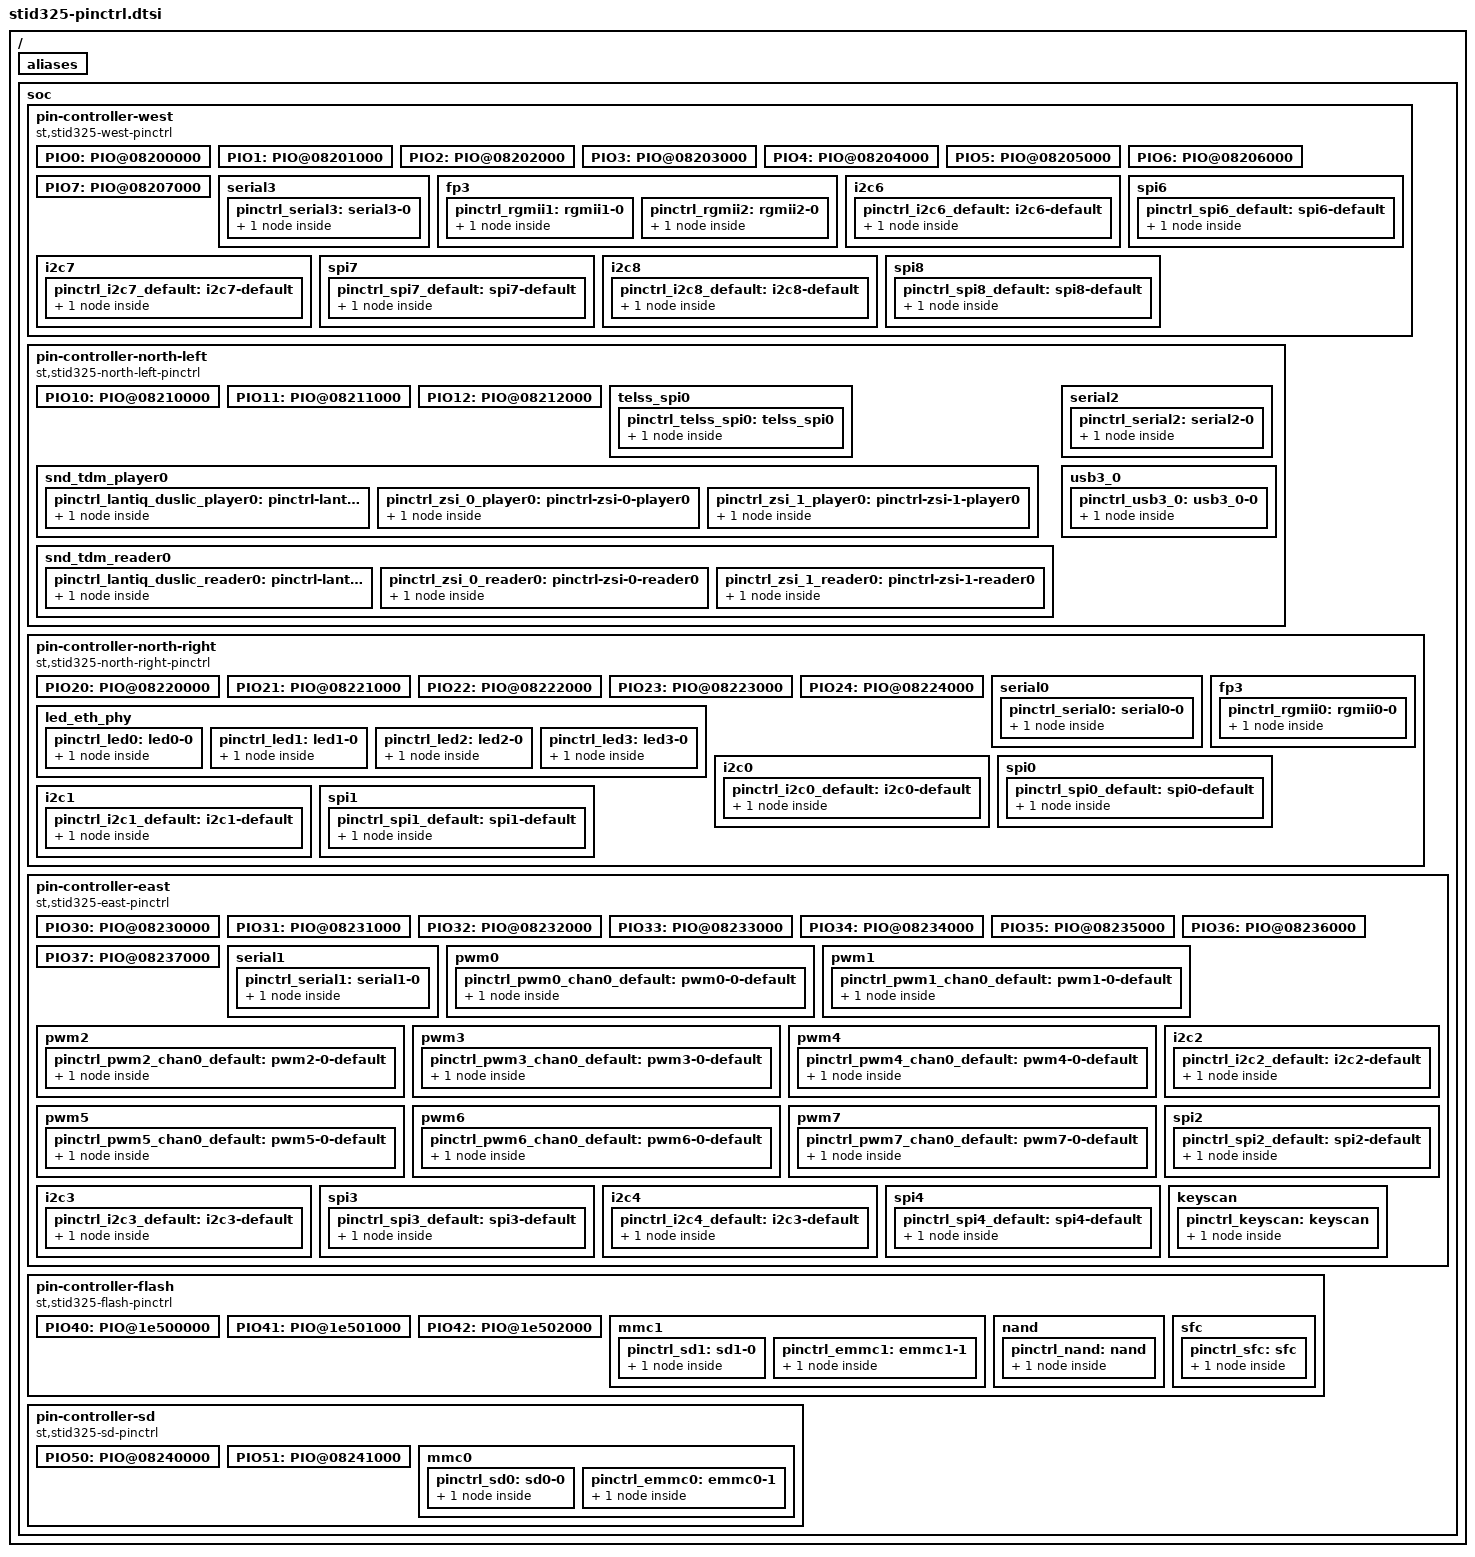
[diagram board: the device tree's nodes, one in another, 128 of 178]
/*
 * Copyright (C) 2015 STMicroelectronics Limited.
 * Author: Carmelo Amoroso <carmelo.amoroso@st.com>
 * Author: Giuseppe Cavallaro <peppe.cavallaro@st.com>
 *
 * This program is free software; you can redistribute it and/or modify
 * it under the terms of the GNU General Public License version 2 as
 * publishhed by the Free Software Foundation.
 */

#include <dt-bindings/pinctrl/st-pincfg.h>
#include <dt-bindings/interrupt-controller/arm-gic.h>

/ {
	aliases {
		/* PIOs for FC_BACKBONE */

		/* PIOs WEST Partition: 0-7 */
		gpio0 = &PIO0;
		gpio1 = &PIO1;
		gpio2 = &PIO2;
		gpio3 = &PIO3;
		gpio4 = &PIO4;
		gpio5 = &PIO5;
		gpio6 = &PIO6;
		gpio7 = &PIO7;

		/* PIOs NORTH_LEFT Partition: 10-12 */
		gpio8 = &PIO10;
		gpio9 = &PIO11;
		gpio10 = &PIO12;

		/* PIOs NORTH_RIGHT Partition: 20-24 */
		gpio11 = &PIO20;
		gpio12 = &PIO21;
		gpio13 = &PIO22;
		gpio14 = &PIO23;
		gpio15 = &PIO24;

		/* PIOs EAST Partition: 30-37 */
		gpio16 = &PIO30;
		gpio17 = &PIO31;
		gpio18 = &PIO32;
		gpio19 = &PIO33;
		gpio20 = &PIO34;
		gpio21 = &PIO35;
		gpio22 = &PIO36;
		gpio23 = &PIO37;

		/* PIOs SOUTH FLASH: 40-42 */
		gpio24 = &PIO40;
		gpio25 = &PIO41;
		gpio26 = &PIO42;

		/* PIOs SD Partition: 50-51 */
		gpio27 = &PIO50;
		gpio28 = &PIO51;
	};

	soc {
		/* FC_BACKBONE PIO_WEST */
		pin-controller-west {
			#address-cells = <1>;
			#size-cells = <1>;
			compatible = "st,stid325-west-pinctrl";
			st,syscfg = <&syscfg_pio_west>;
			ranges = <0 0x08200000 0x8000>;
			reg = <0x0820f080 0x4>;
			reg-names = "irqmux";
			interrupts = <GIC_SPI 185 IRQ_TYPE_NONE>;
			interrupts-names = "irqmux";

			PIO0: PIO@08200000 {
				gpio-controller;
				#gpio-cells = <2>;
				reg = <0x0 0x100>;
				st,bank-name = "PIO0";
				interrupt-controller;
				#interrupt-cells = <2>;
			};

			PIO1: PIO@08201000 {
				gpio-controller;
				#gpio-cells = <2>;
				reg = <0x1000 0x100>;
				st,bank-name = "PIO1";
				interrupt-controller;
				#interrupt-cells = <2>;
			};

			PIO2: PIO@08202000 {
				gpio-controller;
				#gpio-cells = <2>;
				reg = <0x2000 0x100>;
				st,bank-name = "PIO2";
				interrupt-controller;
				#interrupt-cells = <2>;
			};

			PIO3: PIO@08203000 {
				gpio-controller;
				#gpio-cells = <2>;
				reg = <0x3000 0x100>;
				st,bank-name = "PIO3";
				interrupt-controller;
				#interrupt-cells = <2>;
			};

			PIO4: PIO@08204000 {
				gpio-controller;
				#gpio-cells = <2>;
				reg = <0x4000 0x100>;
				st,bank-name = "PIO4";
				interrupt-controller;
				#interrupt-cells = <2>;
			};

			PIO5: PIO@08205000 {
				gpio-controller;
				#gpio-cells = <2>;
				reg = <0x5000 0x100>;
				st,bank-name = "PIO5";
				interrupt-controller;
				#interrupt-cells = <2>;
			};

			PIO6: PIO@08206000 {
				gpio-controller;
				#gpio-cells = <2>;
				reg = <0x6000 0x100>;
				st,bank-name = "PIO6";
				interrupt-controller;
				#interrupt-cells = <2>;
			};

			PIO7: PIO@08207000 {
				gpio-controller;
				#gpio-cells = <2>;
				reg = <0x7000 0x100>;
				st,bank-name = "PIO7";
				interrupt-controller;
				#interrupt-cells = <2>;
			};

			serial3 {
				pinctrl_serial3: serial3-0 {
					st,pins {
						tx = <&PIO7 0 ALT1 OUT>;
						rx = <&PIO7 1 ALT1 IN>;
					};
				};
			};

			/* RGMII 1,2*/
			fp3 {
				pinctrl_rgmii1: rgmii1-0 {
					st,pins {
						txd0 = <&PIO0 0 ALT1 OUT DE_IO 0 CLK_A>;
						txd1 = <&PIO0 1 ALT1 OUT DE_IO 0 CLK_A>;
						txd2 = <&PIO0 2 ALT1 OUT DE_IO 0 CLK_A>;
						txd3 = <&PIO0 3 ALT1 OUT DE_IO 0 CLK_A>;
						txctl = <&PIO0 4 ALT1 OUT NICLK 0 CLK_A>;
						txclk = <&PIO0 5 ALT1 OUT NICLK 0 CLK_A>;
						rxd0 = <&PIO0 6 ALT1 IN DE_IO 0 CLK_A>;
						rxd1 = <&PIO0 7 ALT1 IN DE_IO 0 CLK_A>;
						rxd2 = <&PIO1 0 ALT1 IN DE_IO 0 CLK_A>;
						rxd3 = <&PIO1 1 ALT1 IN DE_IO 0 CLK_A>;
						rxctl = <&PIO1 2 ALT1 IN DE_IO 0 CLK_A>;
						rxclk = <&PIO1 3 ALT1 IN NICLK 0 CLK_A>;
						phyclk = <&PIO1 4 ALT1 OUT NICLK 0 CLK_B>;
					};
				};
				pinctrl_rgmii2: rgmii2-0 {
					st,pins {
						mdio = <&PIO1 5 ALT1 BIDIR BYPASS 0>;
						mdc = <&PIO1 6 ALT1 OUT NICLK 0 CLK_A>;
						mdint = <&PIO1 7 ALT1 IN DE_IO 0 CLK_A>;
						txd0 = <&PIO2 0 ALT1 OUT DE_IO 0 CLK_A>;
						txd1 = <&PIO2 1 ALT1 OUT DE_IO 0 CLK_A>;
						txd2 = <&PIO2 2 ALT1 OUT DE_IO 0 CLK_A>;
						txd3 = <&PIO2 3 ALT1 OUT DE_IO 0 CLK_A>;
						txctl = <&PIO2 4 ALT1 OUT NICLK 0 CLK_A>;
						txclk = <&PIO2 5 ALT1 OUT NICLK 0 CLK_A>;
						rxd0 = <&PIO2 6 ALT1 IN DE_IO 0 CLK_A>;
						rxd1 = <&PIO2 7 ALT1 IN DE_IO 0 CLK_A>;
						rxd2 = <&PIO3 0 ALT1 IN DE_IO 0 CLK_A>;
						rxd3 = <&PIO3 1 ALT1 IN DE_IO 0 CLK_A>;
						rxctl = <&PIO3 2 ALT1 IN DE_IO 0 CLK_A>;
						rxclk = <&PIO3 3 ALT1 IN NICLK 0 CLK_A>;
						phyclk = <&PIO3 4 ALT1 OUT NICLK 0 CLK_B>;
					};
				};
			};

			i2c6 {
				pinctrl_i2c6_default: i2c6-default {
					st,pins {
						sda = <&PIO5 6 ALT1 BIDIR>;
						scl = <&PIO5 5 ALT1 BIDIR>;
					};
				};
			};
			spi6 {
				pinctrl_spi6_default: spi6-default {
					st,pins {
						mtsr = <&PIO5 6 ALT1 BIDIR>;
						mrst = <&PIO5 7 ALT1 BIDIR>;
						scl = <&PIO5 5 ALT1 BIDIR>;
					};
				};
			};
			i2c7 {
				pinctrl_i2c7_default: i2c7-default {
					st,pins {
						sda = <&PIO5 3 ALT1 BIDIR>;
						scl = <&PIO5 2 ALT1 BIDIR>;
					};
				};
			};
			spi7 {
				pinctrl_spi7_default: spi7-default {
					st,pins {
						mtsr = <&PIO6 3 ALT1 BIDIR>;
						mrst = <&PIO6 4 ALT1 BIDIR>;
						scl = <&PIO6 2 ALT1 BIDIR>;
					};
				};
			};
			i2c8 {
				pinctrl_i2c8_default: i2c8-default {
					st,pins {
						sda = <&PIO6 6 ALT1 BIDIR>;
						scl = <&PIO6 5 ALT1 BIDIR>;
					};
				};
			};
			spi8 {
				pinctrl_spi8_default: spi8-default {
					st,pins {
						mtsr = <&PIO6 6 ALT1 BIDIR>;
						mrst = <&PIO6 7 ALT1 BIDIR>;
						scl = <&PIO6 5 ALT1 BIDIR>;
					};
				};
			};
		};

		/* FC_BACKBONE PIO_NORTH_LEFT */
		pin-controller-north-left {
			#address-cells = <1>;
			#size-cells = <1>;
			compatible = "st,stid325-north-left-pinctrl";
			st,syscfg = <&syscfg_pio_north_left>;
			ranges = <0 0x08210000 0x3000>;
			reg = <0x0821f080 0x4>;
			reg-names = "irqmux";
			interrupts = <GIC_SPI 183 IRQ_TYPE_NONE>;
			interrupts-names = "irqmux";

			PIO10: PIO@08210000 {
				gpio-controller;
				#gpio-cells = <2>;
				reg = <0x0 0x100>;
				st,bank-name = "PIO10";
				interrupt-controller;
				#interrupt-cells = <2>;
			};

			PIO11: PIO@08211000 {
				gpio-controller;
				#gpio-cells = <2>;
				reg = <0x1000 0x100>;
				st,bank-name = "PIO11";
				interrupt-controller;
				#interrupt-cells = <2>;
			};

			PIO12: PIO@08212000 {
				gpio-controller;
				#gpio-cells = <2>;
				reg = <0x2000 0x100>;
				st,bank-name = "PIO12";
				interrupt-controller;
				#interrupt-cells = <2>;
			};

			telss_spi0 {
				pinctrl_telss_spi0: telss_spi0 {
					st,pins {
						tel-spi-clk = <&PIO11 1 ALT1 OUT>;
						tel-spi-mosi = <&PIO11 2 ALT1 OUT>;
						tel-spi-miso = <&PIO11 3 ALT1 IN>;
					};
				};
			};

			snd_tdm_player0 {
				pinctrl_lantiq_duslic_player0: pinctrl-lantiq-duslic-player0 {
					st,pins {
						PCLK = <&PIO10 5 ALT1 OUT>;
						DTX = <&PIO10 6 ALT1 OUT>;
						FSYNC = <&PIO12 0 ALT2 OUT>;
					};
				};
				pinctrl_zsi_0_player0: pinctrl-zsi-0-player0 {
					st,pins {
						PCLK = <&PIO11 7 ALT1 OUT>;
						DTX = <&PIO12 1 ALT1 OUT>;
						FSYNC = <&PIO12 0 ALT1 OUT>;
					};
				};
				pinctrl_zsi_1_player0: pinctrl-zsi-1-player0 {
					st,pins {
						PCLK = <&PIO11 0 ALT2 OUT>;
						DTX = <&PIO11 5 ALT2 OUT>;
						FSYNC = <&PIO11 4 ALT2 OUT>;
					};
				};
			};

			snd_tdm_reader0 {
				pinctrl_lantiq_duslic_reader0: pinctrl-lantiq-duslic-reader0 {
					st,pins {
						DRX = <&PIO10 7 ALT1 IN>;
					};
				};
				pinctrl_zsi_0_reader0: pinctrl-zsi-0-reader0 {
					st,pins {
						DRX = <&PIO12 2 ALT1 IN>;
					};
				};
				pinctrl_zsi_1_reader0: pinctrl-zsi-1-reader0 {
					st,pins {
						DRX = <&PIO11 6 ALT2 IN>;
					};
				};
			};

			serial2 {
				pinctrl_serial2: serial2-0 {
					st,pins {
						tx = <&PIO12 3 ALT1 OUT>;
						rx = <&PIO12 4 ALT1 IN>;
					};
				};
			};

			usb3_0 {
				pinctrl_usb3_0: usb3_0-0 {
					st,pins {
						oc-detect = <&PIO12 5 ALT1 IN>;
						pwr-enable = <&PIO12 6 ALT1 OUT>;
					};
				};
			};
		};

		/* FC_BACKBONE PIO_NORTH_RIGHT */
		pin-controller-north-right {
			#address-cells = <1>;
			#size-cells = <1>;
			compatible = "st,stid325-north-right-pinctrl";
			st,syscfg = <&syscfg_pio_north_right>;
			ranges = <0 0x08220000 0x5000>;
			reg = <0x0822f080 0x4>;
			reg-names = "irqmux";
			interrupts = <GIC_SPI 184 IRQ_TYPE_NONE>;
			interrupts-names = "irqmux";

			PIO20: PIO@08220000 {
				gpio-controller;
				#gpio-cells = <2>;
				reg = <0x0 0x100>;
				st,bank-name = "PIO20";
				interrupt-controller;
				#interrupt-cells = <2>;
			};

			PIO21: PIO@08221000 {
				gpio-controller;
				#gpio-cells = <2>;
				reg = <0x1000 0x100>;
				st,bank-name = "PIO21";
				interrupt-controller;
				#interrupt-cells = <2>;
			};

			PIO22: PIO@08222000 {
				gpio-controller;
				#gpio-cells = <2>;
				reg = <0x2000 0x100>;
				st,bank-name = "PIO22";
				interrupt-controller;
				#interrupt-cells = <2>;
			};

			PIO23: PIO@08223000 {
				gpio-controller;
				#gpio-cells = <2>;
				reg = <0x3000 0x100>;
				st,bank-name = "PIO23";
				interrupt-controller;
				#interrupt-cells = <2>;
			};

			PIO24: PIO@08224000 {
				gpio-controller;
				#gpio-cells = <2>;
				reg = <0x4000 0x100>;
				st,bank-name = "PIO24";
				interrupt-controller;
				#interrupt-cells = <2>;
			};

			serial0 {
				pinctrl_serial0: serial0-0 {
					st,pins {
						tx = <&PIO23 0 ALT1 OUT>;
						rx = <&PIO23 1 ALT1 IN>;
					};
				};
			};

			/* RGMII 0 */
			fp3 {
				pinctrl_rgmii0: rgmii0-0 {
					st,pins {
						txd0 = <&PIO21 0 ALT1 OUT DE_IO 0 CLK_A>;
						txd1 = <&PIO21 1 ALT1 OUT DE_IO 0 CLK_A>;
						txd2 = <&PIO21 2 ALT1 OUT DE_IO 0 CLK_A>;
						txd3 = <&PIO21 3 ALT1 OUT DE_IO 0 CLK_A>;
						txctl = <&PIO21 4 ALT1 OUT NICLK 0 CLK_A>;
						txclk = <&PIO21 5 ALT1 OUT NICLK 0 CLK_A>;
						rxd0 = <&PIO21 6 ALT1 IN DE_IO 0 CLK_A>;
						rxd1 = <&PIO21 7 ALT1 IN DE_IO 0 CLK_A>;
						rxd2 = <&PIO22 0 ALT1 IN DE_IO 0 CLK_A>;
						rxd3 = <&PIO22 1 ALT1 IN DE_IO 0 CLK_A>;
						rxctl = <&PIO22 2 ALT1 IN DE_IO 0 CLK_A>;
						rxclk = <&PIO22 3 ALT1 IN NICLK 0 CLK_A>;
						phyclk = <&PIO22 4 ALT1 OUT NICLK 0 CLK_B>;
						mdio = <&PIO22 5 ALT1 BIDIR BYPASS 0>;
						mdc = <&PIO22 6 ALT1 OUT NICLK 0 CLK_A>;
						mdint = <&PIO22 7 ALT1 IN DE_IO 0 CLK_A>;
					};
				};
			};

			/* LED Control for ETH PHY */
			led_eth_phy {
				pinctrl_led0: led0-0 {
					st,pins {
						blinkb = <&PIO20 0 ALT1 OUT>;
						txrxb = <&PIO20 1 ALT1 OUT>;
					};
				};
				pinctrl_led1: led1-0 {
					st,pins {
						blinkb = <&PIO20 2 ALT1 OUT>;
						txrxb = <&PIO20 3 ALT1 OUT>;
					};
				};
				pinctrl_led2: led2-0 {
					st,pins {
						blinkb = <&PIO20 4 ALT1 OUT>;
						txrxb = <&PIO20 5 ALT1 OUT>;
					};
				};
				pinctrl_led3: led3-0 {
					st,pins {
						blinkb = <&PIO20 6 ALT1 OUT>;
						txrxb = <&PIO20 7 ALT1 OUT>;
					};
				};
			};

			i2c0 {
				pinctrl_i2c0_default: i2c0-default {
					st,pins {
						sda = <&PIO23 5 ALT1 BIDIR>;
						scl = <&PIO23 4 ALT1 BIDIR>;
					};
				};
			};
			spi0 {
				pinctrl_spi0_default: spi0-default {
					st,pins {
						mtsr = <&PIO23 5 ALT1 BIDIR>;
						mrst = <&PIO23 6 ALT1 BIDIR>;
						scl = <&PIO23 4 ALT1 BIDIR>;
					};
				};
			};
			i2c1 {
				pinctrl_i2c1_default: i2c1-default {
					st,pins {
						sda = <&PIO24 0 ALT1 BIDIR>;
						scl = <&PIO23 7 ALT1 BIDIR>;
					};
				};
			};
			spi1 {
				pinctrl_spi1_default: spi1-default {
					st,pins {
						mtsr = <&PIO24 0 ALT1 BIDIR>;
						mrst = <&PIO24 1 ALT1 BIDIR>;
						scl = <&PIO23 7 ALT1 BIDIR>;
					};
				};
			};
		};

		/* FC_BACKBONE PIO_EAST */
		pin-controller-east {
			#address-cells = <1>;
			#size-cells = <1>;
			compatible = "st,stid325-east-pinctrl";
			st,syscfg = <&syscfg_pio_east>;
			ranges = <0 0x08230000 0x8000>;
			reg = <0x0823f080 0x4>;
			reg-names = "irqmux";
			interrupts = <GIC_SPI 186 IRQ_TYPE_NONE>;
			interrupts-names = "irqmux";

			PIO30: PIO@08230000 {
				gpio-controller;
				#gpio-cells = <2>;
				reg = <0x0 0x100>;
				st,bank-name = "PIO30";
				interrupt-controller;
				#interrupt-cells = <2>;
			};

			PIO31: PIO@08231000 {
				gpio-controller;
				#gpio-cells = <2>;
				reg = <0x1000 0x100>;
				st,bank-name = "PIO31";
				interrupt-controller;
				#interrupt-cells = <2>;
			};

			PIO32: PIO@08232000 {
				gpio-controller;
				#gpio-cells = <2>;
				reg = <0x2000 0x100>;
				st,bank-name = "PIO32";
				interrupt-controller;
				#interrupt-cells = <2>;
			};

			PIO33: PIO@08233000 {
				gpio-controller;
				#gpio-cells = <2>;
				reg = <0x3000 0x100>;
				st,bank-name = "PIO33";
				interrupt-controller;
				#interrupt-cells = <2>;
			};

			PIO34: PIO@08234000 {
				gpio-controller;
				#gpio-cells = <2>;
				reg = <0x4000 0x100>;
				st,bank-name = "PIO34";
				interrupt-controller;
				#interrupt-cells = <2>;
			};

			PIO35: PIO@08235000 {
				gpio-controller;
				#gpio-cells = <2>;
				reg = <0x5000 0x100>;
				st,bank-name = "PIO35";
				interrupt-controller;
				#interrupt-cells = <2>;
			};

			PIO36: PIO@08236000 {
				gpio-controller;
				#gpio-cells = <2>;
				reg = <0x6000 0x100>;
				st,bank-name = "PIO36";
				interrupt-controller;
				#interrupt-cells = <2>;
			};

			PIO37: PIO@08237000 {
				gpio-controller;
				#gpio-cells = <2>;
				reg = <0x7000 0x100>;
				st,bank-name = "PIO37";
				interrupt-controller;
				#interrupt-cells = <2>;
			};

			serial1 {
				pinctrl_serial1: serial1-0 {
					st,pins {
						tx = <&PIO33 3 ALT1 OUT>;
						rx = <&PIO33 4 ALT1 IN>;
					};
				};
			};

			pwm0 {
				pinctrl_pwm0_chan0_default: pwm0-0-default {
					st,pins {
						pwm-out = <&PIO35 2 ALT1 OUT>;
					};
				};
			};
			pwm1 {
				pinctrl_pwm1_chan0_default: pwm1-0-default {
					st,pins {
						pwm-out = <&PIO35 3 ALT1 OUT>;
					};
				};
			};
			pwm2 {
				pinctrl_pwm2_chan0_default: pwm2-0-default {
					st,pins {
						pwm-out = <&PIO35 4 ALT1 OUT>;
					};
				};
			};
			pwm3 {
				pinctrl_pwm3_chan0_default: pwm3-0-default {
					st,pins {
						pwm-out = <&PIO35 5 ALT1 OUT>;
					};
				};
			};
			pwm4 {
				pinctrl_pwm4_chan0_default: pwm4-0-default {
					st,pins {
						pwm-out = <&PIO36 0 ALT1 OUT>;
					};
				};
			};
			pwm5 {
				pinctrl_pwm5_chan0_default: pwm5-0-default {
					st,pins {
						pwm-out = <&PIO36 1 ALT1 OUT>;
					};
				};
			};
			pwm6 {
				pinctrl_pwm6_chan0_default: pwm6-0-default {
					st,pins {
						pwm-out = <&PIO36 2 ALT1 OUT>;
					};
				};
			};
			pwm7 {
				pinctrl_pwm7_chan0_default: pwm7-0-default {
					st,pins {
						pwm-out = <&PIO36 3 ALT1 OUT>;
					};
				};
			};

			i2c2 {
				pinctrl_i2c2_default: i2c2-default {
					st,pins {
						sda = <&PIO33 6 ALT1 BIDIR>;
						scl = <&PIO33 5 ALT1 BIDIR>;
					};
				};
			};
			spi2 {
				pinctrl_spi2_default: spi2-default {
					st,pins {
						mtsr = <&PIO33 6 ALT1 BIDIR>;
						mrst = <&PIO33 7 ALT1 BIDIR>;
						scl = <&PIO33 5 ALT1 BIDIR>;
					};
				};
			};
			i2c3 {
				pinctrl_i2c3_default: i2c3-default {
					st,pins {
						sda = <&PIO34 1 ALT1 BIDIR>;
						scl = <&PIO34 0 ALT1 BIDIR>;
					};
				};
			};
			spi3 {
				pinctrl_spi3_default: spi3-default {
					st,pins {
						mtsr = <&PIO34 1 ALT1 BIDIR>;
						mrst = <&PIO34 2 ALT1 BIDIR>;
						scl = <&PIO34 0 ALT1 BIDIR>;
					};
				};
			};
			i2c4 {
				pinctrl_i2c4_default: i2c3-default {
					st,pins {
						sda = <&PIO34 4 ALT1 BIDIR>;
						scl = <&PIO34 3 ALT1 BIDIR>;
					};
				};
			};
			spi4 {
				pinctrl_spi4_default: spi4-default {
					st,pins {
						mtsr = <&PIO34 4 ALT1 BIDIR>;
						mrst = <&PIO34 5 ALT1 BIDIR>;
						scl = <&PIO34 3 ALT1 BIDIR>;
					};
				};
			};

			keyscan {
				pinctrl_keyscan: keyscan {
					st,pins {
						keyin0 = <&PIO37 0 ALT6 IN>;
						keyin1 = <&PIO37 1 ALT4 IN>;
						keyin2 = <&PIO37 2 ALT2 IN>;
						keyin3 = <&PIO37 3 ALT2 IN>;
						keyout0 = <&PIO37 4 ALT4 OUT>;
						keyout1 = <&PIO37 5 ALT2 OUT>;
						keyout2 = <&PIO37 6 ALT2 OUT>;
						keyout3 = <&PIO37 7 ALT2 OUT>;
					};
				};
			};
		};

		/* PIOs SOUTH FLASH: 40-42 */
		pin-controller-flash {
			#address-cells = <1>;
			#size-cells = <1>;
			compatible = "st,stid325-flash-pinctrl";
			st,syscfg = <&syscfg_pio_flash>;
			ranges	 = <0 0x1e500000 0x3000>;
			reg = <0x1e50f080 0x4>;
			reg-names = "irqmux";
			interrupts = <GIC_SPI 189 IRQ_TYPE_NONE>;
			interrupts-names = "irqmux";

			PIO40: PIO@1e500000 {
				gpio-controller;
				#gpio-cells = <2>;
				reg = <0x0 0x100>;
				st,bank-name = "PIO40";
				interrupt-controller;
				#interrupt-cells = <2>;
			};

			PIO41: PIO@1e501000 {
				gpio-controller;
				#gpio-cells = <2>;
				reg = <0x1000 0x100>;
				st,bank-name = "PIO41";
				interrupt-controller;
				#interrupt-cells = <2>;
			};

			PIO42: PIO@1e502000 {
				gpio-controller;
				#gpio-cells = <2>;
				reg = <0x2000 0x100>;
				st,bank-name = "PIO42";
				interrupt-controller;
				#interrupt-cells = <2>;
			};

			/* MMC/SD from flashSS */
			mmc1 {
				pinctrl_sd1: sd1-0 {
					st,pins {
						sd_clk = <&PIO40 6 ALT2 BIDIR>;
						sd_cmd = <&PIO40 7 ALT2 BIDIR>;
						sd_d0 = <&PIO41 0 ALT2 BIDIR>;
						sd_d1 = <&PIO41 1 ALT2 BIDIR>;
						sd_d2 = <&PIO41 2 ALT2 BIDIR>;
						sd_d3 = <&PIO41 3 ALT2 BIDIR>;
						sd_led = <&PIO42 0 ALT2 BIDIR>;
						sd_pwren = <&PIO42 2 ALT2 BIDIR>;
						sd_vsel = <&PIO42 3 ALT2 BIDIR>;
						sd_cd = <&PIO42 4 ALT2 BIDIR>;
						sd_wp = <&PIO42 5 ALT2 BIDIR>;
					};
				};
				pinctrl_emmc1: emmc1-1 {
					st,pins {
						emmc_clk = <&PIO40 6 ALT1 BIDIR>;
						emmc_cmd = <&PIO40 7 ALT1 BIDIR>;
						emmc_d0 = <&PIO41 0 ALT1 BIDIR>;
						emmc_d1 = <&PIO41 1 ALT1 BIDIR>;
						emmc_d2 = <&PIO41 2 ALT1 BIDIR>;
						emmc_d3 = <&PIO41 3 ALT1 BIDIR>;
						emmc_d4 = <&PIO41 4 ALT1 BIDIR>;
						emmc_d5 = <&PIO41 5 ALT1 BIDIR>;
						emmc_d6 = <&PIO41 6 ALT1 BIDIR>;
						emmc_d7 = <&PIO41 7 ALT1 BIDIR>;
					};
				};
			};

			/* NAND (Async mode)*/
			nand {
				pinctrl_nand: nand {
					st,pins {
						nand_cs2 = <&PIO40 4 ALT3 OUT>;
						nand_cs3 = <&PIO40 5 ALT3 OUT>;
						nand_cs1 = <&PIO40 6 ALT3 OUT>;
						nand_cs0 = <&PIO40 7 ALT3 OUT>;
						nand_d0 = <&PIO41 0 ALT3 BIDIR>;
						nand_d1 = <&PIO41 1 ALT3 BIDIR>;
						nand_d2 = <&PIO41 2 ALT3 BIDIR>;
						nand_d3 = <&PIO41 3 ALT3 BIDIR>;
						nand_d4 = <&PIO41 4 ALT3 BIDIR>;
						nand_d5 = <&PIO41 5 ALT3 BIDIR>;
						nand_d6 = <&PIO41 6 ALT3 BIDIR>;
						nand_d7 = <&PIO41 7 ALT3 BIDIR>;
						nand_we = <&PIO42 0 ALT3 OUT>;
						nand_ale = <&PIO42 2 ALT3 OUT>;
						nand_cle = <&PIO42 3 ALT3 OUT>;
						nand_rnb = <&PIO42 4 ALT3 IN>;
						nand_ren = <&PIO42 5 ALT3 OUT>;
					};
				};
			};

			/* SPI SFC */
			sfc {
				pinctrl_sfc: sfc {
					st,pins {
						spi-sfc-cs = <&PIO40 0 ALT1 OUT>;
						spi-sfc-clk = <&PIO40 1 ALT1 OUT>;
						spi-sfc-d0 = <&PIO40 2 ALT1 OUT>;
						spi-sfc-d1 = <&PIO40 3 ALT1 IN>;
						spi-sfc-d2 = <&PIO40 4 ALT1 OUT>;
						spi-sfc-d3 = <&PIO40 5 ALT1 OUT>;
					};
				};
			};
		};

		/* FC_BACKBONE PIO_SD */
		pin-controller-sd {
			#address-cells = <1>;
			#size-cells = <1>;
			compatible = "st,stid325-sd-pinctrl";
			st,syscfg = <&syscfg_pio_sd>;
			ranges = <0 0x08240000 0x2000>;
			reg = <0x0824f080 0x4>;
			reg-names = "irqmux";
			interrupts = <GIC_SPI 187 IRQ_TYPE_NONE>;
			interrupts-names = "irqmux";

			PIO50: PIO@08240000 {
				gpio-controller;
				#gpio-cells = <2>;
				reg = <0x0 0x100>;
				st,bank-name = "PIO50";
				interrupt-controller;
				#interrupt-cells = <2>;
			};

			PIO51: PIO@08241000 {
				gpio-controller;
				#gpio-cells = <2>;
				reg = <0x1000 0x100>;
				st,bank-name = "PIO51";
				interrupt-controller;
				#interrupt-cells = <2>;
			};

			/* Stand-alone MMC/SD with SD PHY on FC 11 */
			mmc0 {
				pinctrl_sd0: sd0-0 {
					st,pins {
						sd_clk = <&PIO50 0 ALT2 BIDIR>;
						sd_cmd = <&PIO50 1 ALT2 BIDIR>;
						sd_d0 = <&PIO50 2 ALT2 BIDIR>;
						sd_d1 = <&PIO50 3 ALT2 BIDIR>;
						sd_d2 = <&PIO50 4 ALT2 BIDIR>;
						sd_d3 = <&PIO50 5 ALT2 BIDIR>;
						sd_cd = <&PIO50 6 ALT2 IN>;
						sd_wp = <&PIO50 7 ALT2 IN>;
						sd_pwren = <&PIO51 0 ALT2 OUT>;
						sd_vsel = <&PIO51 1 ALT2 OUT>;
						sd_led = <&PIO51 2 ALT2 OUT>;
					};
				};
				pinctrl_emmc0: emmc0-1 {
					st,pins {
						emmc_clk = <&PIO50 0 ALT1 OUT>;
						emmc_cmd = <&PIO50 1 ALT1 BIDIR>;
						emmc_d0 = <&PIO50 2 ALT1 BIDIR>;
						emmc_d1 = <&PIO50 3 ALT1 BIDIR>;
						emmc_d2 = <&PIO50 4 ALT1 BIDIR>;
						emmc_d3 = <&PIO50 5 ALT1 BIDIR>;
						emmc_d4 = <&PIO50 6 ALT1 BIDIR>;
						emmc_d5 = <&PIO50 7 ALT1 BIDIR>;
						emmc_d6 = <&PIO51 0 ALT1 BIDIR>;
						emmc_d7 = <&PIO51 1 ALT1 BIDIR>;
					};
				};
			};
		};
	};
};
